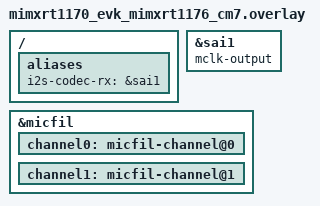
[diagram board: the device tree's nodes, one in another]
/*
 * Copyright 2026 NXP
 *
 * SPDX-License-Identifier: Apache-2.0
 */

/ {
	aliases {
		/* SAI1 carries both directions: the WM8962 is full duplex on it. */
		i2s-codec-rx = &sai1;
	};
};

&sai1 {
	mclk-output;
};

dmic_dev: &micfil {
	channel0: micfil-channel@0 {
		status = "okay";
	};

	channel1: micfil-channel@1 {
		status = "okay";
	};
};
